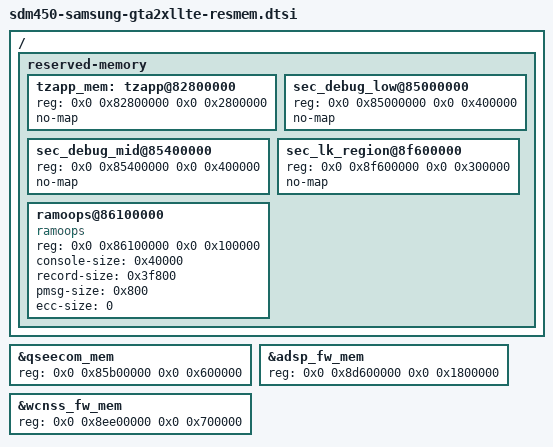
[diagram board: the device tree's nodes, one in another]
/* Samsung LK/TZ firmware carveouts absent from msm8953.dtsi; leaving them
 * unreserved lets Linux allocate into firmware RAM and the device bootloops. */

/ {
	reserved-memory {
		tzapp_mem: tzapp@82800000 {
			reg = <0x0 0x82800000 0x0 0x2800000>;
			no-map;
		};

		sec_debug_low@85000000 {
			reg = <0x0 0x85000000 0x0 0x400000>;
			no-map;
		};

		sec_debug_mid@85400000 {
			reg = <0x0 0x85400000 0x0 0x400000>;
			no-map;
		};

		sec_lk_region@8f600000 {
			reg = <0x0 0x8f600000 0x0 0x300000>;
			no-map;
		};

		ramoops@86100000 {
			compatible = "ramoops";
			reg = <0x0 0x86100000 0x0 0x100000>;
			console-size = <0x40000>;
			record-size  = <0x3f800>;
			pmsg-size    = <0x800>;
			ecc-size     = <0>;
		};
	};
};

/* adsp size and wcnss address are coupled: adsp ends exactly where wcnss starts */
&qseecom_mem { reg = <0x0 0x85b00000 0x0 0x600000>; };
&adsp_fw_mem { reg = <0x0 0x8d600000 0x0 0x1800000>; };
&wcnss_fw_mem { reg = <0x0 0x8ee00000 0x0 0x700000>; };
